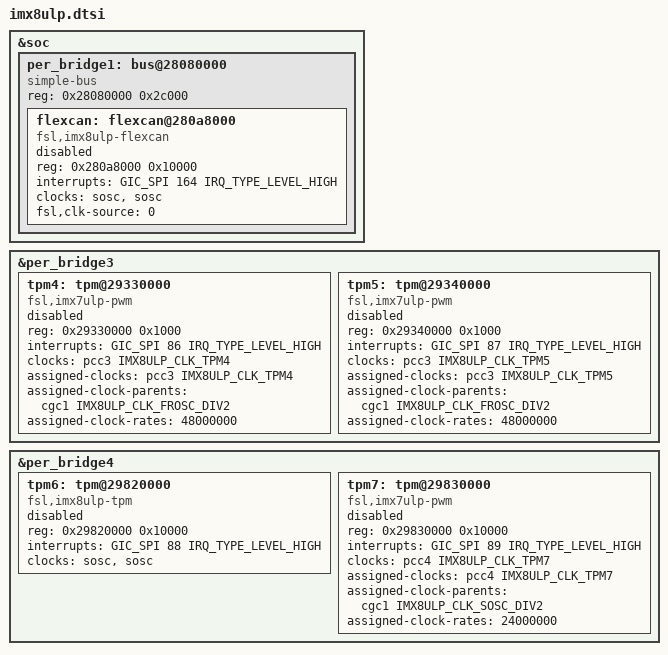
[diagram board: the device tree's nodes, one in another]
// SPDX-License-Identifier: GPL-2.0
/*
* Copyright 2024 F&S Elektronik Systeme GmbH
*
* This program is free software; you can redistribute it and/or modify
* it under the terms of the GNU General Public License version 2 as
* published by the Free Software Foundation.
*
* This program is distributed in the hope that it will be useful,
* but WITHOUT ANY WARRANTY; without even the implied warranty of
* MERCHANTABILITY or FITNESS FOR A PARTICULAR PURPOSE.  See the
* GNU General Public License for more details.
*/

/dts-v1/;

#include "../freescale/imx8ulp.dtsi"

&soc {
	per_bridge1: bus@28080000 {
		compatible = "simple-bus";
		reg = <0x28080000 0x2c000>;
		#address-cells = <1>;
		#size-cells = <1>;
		ranges;

		/*
		* NOTE: Feature CAN_IN_APD is required in BOARD-CFG (NBOOT)
		* realtimed version > 0.3.3 is required for CAN support !
		*/
		flexcan: flexcan@280a8000 {
			compatible = "fsl,imx8ulp-flexcan";
			reg = <0x280a8000 0x10000>;
			interrupts = <GIC_SPI 164 IRQ_TYPE_LEVEL_HIGH>;
			clocks = <&sosc>,
					<&sosc>;
			clock-names = "ipg", "per";
			// reserved bit, keep reset default!
			fsl,clk-source = /bits/ 8 <0>;
			status = "disabled";
		};
	};
};

/delete-node/ &tpm5;

&per_bridge3 {
	tpm4: tpm@29330000 {
		compatible = "fsl,imx7ulp-pwm";
		reg = <0x29330000 0x1000>;
		interrupts = <GIC_SPI 86 IRQ_TYPE_LEVEL_HIGH>;
		clocks = <&pcc3 IMX8ULP_CLK_TPM4>;
		assigned-clocks = <&pcc3 IMX8ULP_CLK_TPM4>;
		assigned-clock-parents = <&cgc1 IMX8ULP_CLK_FROSC_DIV2>;
		assigned-clock-rates = <48000000>;
		#pwm-cells = <3>;
		status = "disabled";
	};

	tpm5: tpm@29340000 {
		compatible = "fsl,imx7ulp-pwm";
		reg = <0x29340000 0x1000>;
		interrupts = <GIC_SPI 87 IRQ_TYPE_LEVEL_HIGH>;
		clocks = <&pcc3 IMX8ULP_CLK_TPM5>;
		assigned-clocks = <&pcc3 IMX8ULP_CLK_TPM5>;
		assigned-clock-parents = <&cgc1 IMX8ULP_CLK_FROSC_DIV2>;
		assigned-clock-rates = <48000000>;
		#pwm-cells = <3>;
		status = "disabled";
	};
};

&per_bridge4 {
	/*
	 * NOTE: TPM6 is used as CLOCKSOURCE for System Time
	 */
	tpm6: tpm@29820000 {
		compatible = "fsl,imx8ulp-tpm", "fsl,imx7ulp-tpm";
		reg = <0x29820000 0x10000>;
		interrupts = <GIC_SPI 88 IRQ_TYPE_LEVEL_HIGH>;
		clocks = <&sosc>, <&sosc>;
		clock-names = "ipg", "per";
		status = "disabled";
	};

	tpm7: tpm@29830000 {
		compatible = "fsl,imx7ulp-pwm";
		reg = <0x29830000 0x10000>;
		interrupts = <GIC_SPI 89 IRQ_TYPE_LEVEL_HIGH>;
		clocks = <&pcc4 IMX8ULP_CLK_TPM7>;
		assigned-clocks = <&pcc4 IMX8ULP_CLK_TPM7>;
		assigned-clock-parents = <&cgc1 IMX8ULP_CLK_SOSC_DIV2>;
		assigned-clock-rates = <24000000>;
		#pwm-cells = <3>;
		status = "disabled";
	};
};
